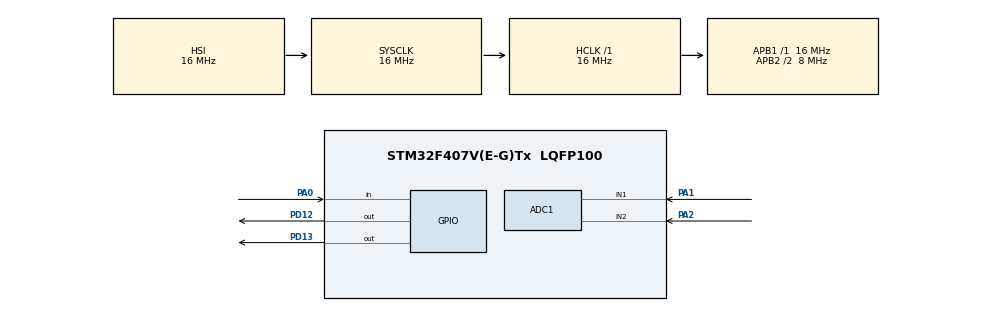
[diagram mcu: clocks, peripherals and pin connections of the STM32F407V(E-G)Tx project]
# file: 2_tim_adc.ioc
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ADC1.Channel-0\#ChannelRegularConversion=ADC_CHANNEL_1
ADC1.Channel-1\#ChannelRegularConversion=ADC_CHANNEL_2
ADC1.ContinuousConvMode=ENABLE
ADC1.NbrOfConversion=2
ADC1.NbrOfConversionFlag=1
ADC1.Rank-0\#ChannelRegularConversion=1
ADC1.Rank-1\#ChannelRegularConversion=2
ADC1.SamplingTime-0\#ChannelRegularConversion=ADC_SAMPLETIME_56CYCLES
ADC1.SamplingTime-1\#ChannelRegularConversion=ADC_SAMPLETIME_56CYCLES
ADC1.master=1
Mcu.Family=STM32F4
Mcu.Name=STM32F407V(E-G)Tx
Mcu.Package=LQFP100
NVIC.PriorityGroup=NVIC_PRIORITYGROUP_4
PA0-WKUP.Signal=GPIO_Input
PA1.Signal=ADCx_IN1
PA13.Mode=Serial_Wire
PA13.Signal=SYS_JTMS-SWDIO
PA14.Mode=Serial_Wire
PA14.Signal=SYS_JTCK-SWCLK
PA2.Signal=ADCx_IN2
PD12.Signal=GPIO_Output
PD13.Signal=GPIO_Output
ProjectManager.HeapSize=0x200
ProjectManager.StackSize=0x400
ProjectManager.TargetToolchain=MDK-ARM V5
RCC.48MHZClocksFreq_Value=25000000
RCC.AHBFreq_Value=16000000
RCC.APB1Freq_Value=16000000
RCC.APB1TimFreq_Value=16000000
RCC.APB2CLKDivider=RCC_HCLK_DIV2
RCC.APB2Freq_Value=8000000
RCC.APB2TimFreq_Value=16000000
RCC.CortexFreq_Value=16000000
RCC.HCLKFreq_Value=16000000
RCC.HSE_VALUE=8000000
RCC.HSI_VALUE=16000000
RCC.LSE_VALUE=32768
RCC.PLLI2SN=50
RCC.PLLM=8
RCC.PLLN=50
RCC.SYSCLKFreq_VALUE=16000000
RCC.VCOOutputFreq_Value=100000000
SH.ADCx_IN1.0=ADC1_IN1,IN1
SH.ADCx_IN2.0=ADC1_IN2,IN2
TIM2.Period=9999
TIM2.Prescaler=16000-1
VP_TIM2_VS_ClockSourceINT.Mode=Internal
board=custom

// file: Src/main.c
/* USER CODE BEGIN Header */
/**
  ******************************************************************************
  * @file           : main.c
  * @brief          : Main program body
  ******************************************************************************
  ** This notice applies to any and all portions of this file
  * that are not between comment pairs USER CODE BEGIN and
  * USER CODE END. Other portions of this file, whether
  * inserted by the user or by software development tools
  * are owned by their respective copyright owners.
  *
  * COPYRIGHT(c) 2020 STMicroelectronics
  *
  * Redistribution and use in source and binary forms, with or without modification,
  * are permitted provided that the following conditions are met:
  *   1. Redistributions of source code must retain the above copyright notice,
  *      this list of conditions and the following disclaimer.
  *   2. Redistributions in binary form must reproduce the above copyright notice,
  *      this list of conditions and the following disclaimer in the documentation
  *      and/or other materials provided with the distribution.
  *   3. Neither the name of STMicroelectronics nor the names of its contributors
  *      may be used to endorse or promote products derived from this software
  *      without specific prior written permission.
  *
  * THIS SOFTWARE IS PROVIDED BY THE COPYRIGHT HOLDERS AND CONTRIBUTORS "AS IS"
  * AND ANY EXPRESS OR IMPLIED WARRANTIES, INCLUDING, BUT NOT LIMITED TO, THE
  * IMPLIED WARRANTIES OF MERCHANTABILITY AND FITNESS FOR A PARTICULAR PURPOSE ARE
  * DISCLAIMED. IN NO EVENT SHALL THE COPYRIGHT HOLDER OR CONTRIBUTORS BE LIABLE
  * FOR ANY DIRECT, INDIRECT, INCIDENTAL, SPECIAL, EXEMPLARY, OR CONSEQUENTIAL
  * DAMAGES (INCLUDING, BUT NOT LIMITED TO, PROCUREMENT OF SUBSTITUTE GOODS OR
  * SERVICES; LOSS OF USE, DATA, OR PROFITS; OR BUSINESS INTERRUPTION) HOWEVER
  * CAUSED AND ON ANY THEORY OF LIABILITY, WHETHER IN CONTRACT, STRICT LIABILITY,
  * OR TORT (INCLUDING NEGLIGENCE OR OTHERWISE) ARISING IN ANY WAY OUT OF THE USE
  * OF THIS SOFTWARE, EVEN IF ADVISED OF THE POSSIBILITY OF SUCH DAMAGE.
  *
  ******************************************************************************
  */
/* USER CODE END Header */

#include "main.h"

/* USER CODE BEGIN PD */
uint16_t sayac=0,count=0;
uint16_t channel_1,channel_2 ; // kanal 1 2  datasi
/* USER CODE END PD */

ADC_HandleTypeDef hadc1;

TIM_HandleTypeDef htim2;

void SystemClock_Config(void);
static void MX_GPIO_Init(void);
static void MX_TIM2_Init(void);
static void MX_ADC1_Init(void);
/* USER CODE BEGIN PFP */

void Buton_Oku(void)
{
	  while((HAL_GPIO_ReadPin(GPIOA,GPIO_PIN_0))!=0 )
  {
    	HAL_TIM_Base_Start(&htim2);
	    sayac= __HAL_TIM_GetCounter(&htim2);

	 while(sayac>=3000 )
	 {

			 HAL_GPIO_WritePin(GPIOD,GPIO_PIN_12|GPIO_PIN_13,GPIO_PIN_SET);
			 channel_1 = HAL_ADC_GetValue(&hadc1);
		     channel_2 = HAL_ADC_GetValue(&hadc1);
		     HAL_Delay(500);

		     if( count==2 )
				{
					__HAL_TIM_SetCounter(&htim2,0);
					sayac= __HAL_TIM_GetCounter(&htim2);
					HAL_GPIO_WritePin(GPIOD,GPIO_PIN_12|GPIO_PIN_13,GPIO_PIN_RESET);
					count=0;
	 			}

	  }

  }
}

int main(void)
{

  /* MCU Configuration--------------------------------------------------------*/

  /* Reset of all peripherals, Initializes the Flash interface and the Systick. */
  HAL_Init();

  /* Configure the system clock */
  SystemClock_Config();

  /* Initialize all configured peripherals */
  MX_GPIO_Init();
  MX_TIM2_Init();
  MX_ADC1_Init();
  /* USER CODE BEGIN 2 */
  HAL_ADC_Start(&hadc1); // adc yi start ettik. ADC1'i.
  /* USER CODE END 2 */

  /* Infinite loop */
  while (1)
  {
  Buton_Oku();
  }
}

void SystemClock_Config(void)
{
  RCC_OscInitTypeDef RCC_OscInitStruct = {0};
  RCC_ClkInitTypeDef RCC_ClkInitStruct = {0};

  /**Configure the main internal regulator output voltage
  */
  __HAL_RCC_PWR_CLK_ENABLE();
  __HAL_PWR_VOLTAGESCALING_CONFIG(PWR_REGULATOR_VOLTAGE_SCALE1);
  /**Initializes the CPU, AHB and APB busses clocks
  */
  RCC_OscInitStruct.OscillatorType = RCC_OSCILLATORTYPE_HSI;
  RCC_OscInitStruct.HSIState = RCC_HSI_ON;
  RCC_OscInitStruct.HSICalibrationValue = RCC_HSICALIBRATION_DEFAULT;
  RCC_OscInitStruct.PLL.PLLState = RCC_PLL_NONE;
  if (HAL_RCC_OscConfig(&RCC_OscInitStruct) != HAL_OK)
  {
    Error_Handler();
  }
  /**Initializes the CPU, AHB and APB busses clocks
  */
  RCC_ClkInitStruct.ClockType = RCC_CLOCKTYPE_HCLK|RCC_CLOCKTYPE_SYSCLK
                              |RCC_CLOCKTYPE_PCLK1|RCC_CLOCKTYPE_PCLK2;
  RCC_ClkInitStruct.SYSCLKSource = RCC_SYSCLKSOURCE_HSI;
  RCC_ClkInitStruct.AHBCLKDivider = RCC_SYSCLK_DIV1;
  RCC_ClkInitStruct.APB1CLKDivider = RCC_HCLK_DIV1;
  RCC_ClkInitStruct.APB2CLKDivider = RCC_HCLK_DIV2;

  if (HAL_RCC_ClockConfig(&RCC_ClkInitStruct, FLASH_LATENCY_0) != HAL_OK)
  {
    Error_Handler();
  }
}

static void MX_ADC1_Init(void)
{

  ADC_ChannelConfTypeDef sConfig = {0};

  /**Configure the global features of the ADC (Clock, Resolution, Data Alignment and number of conversion)
  */
  hadc1.Instance = ADC1;
  hadc1.Init.ClockPrescaler = ADC_CLOCK_SYNC_PCLK_DIV2;
  hadc1.Init.Resolution = ADC_RESOLUTION_12B;
  hadc1.Init.ScanConvMode = ENABLE;
  hadc1.Init.ContinuousConvMode = ENABLE;
  hadc1.Init.DiscontinuousConvMode = DISABLE;
  hadc1.Init.ExternalTrigConvEdge = ADC_EXTERNALTRIGCONVEDGE_NONE;
  hadc1.Init.ExternalTrigConv = ADC_SOFTWARE_START;
  hadc1.Init.DataAlign = ADC_DATAALIGN_RIGHT;
  hadc1.Init.NbrOfConversion = 2;
  hadc1.Init.DMAContinuousRequests = DISABLE;
  hadc1.Init.EOCSelection = ADC_EOC_SINGLE_CONV;
  if (HAL_ADC_Init(&hadc1) != HAL_OK)
  {
    Error_Handler();
  }
  /**Configure for the selected ADC regular channel its corresponding rank in the sequencer and its sample time.
  */
  sConfig.Channel = ADC_CHANNEL_1;
  sConfig.Rank = 1;
  sConfig.SamplingTime = ADC_SAMPLETIME_3CYCLES;
  if (HAL_ADC_ConfigChannel(&hadc1, &sConfig) != HAL_OK)
  {
    Error_Handler();
  }
  /**Configure for the selected ADC regular channel its corresponding rank in the sequencer and its sample time.
  */
  sConfig.Channel = ADC_CHANNEL_2;
  sConfig.Rank = 2;
  if (HAL_ADC_ConfigChannel(&hadc1, &sConfig) != HAL_OK)
  {
    Error_Handler();
  }

}

static void MX_TIM2_Init(void)
{

  TIM_ClockConfigTypeDef sClockSourceConfig = {0};
  TIM_MasterConfigTypeDef sMasterConfig = {0};

  htim2.Instance = TIM2;
  htim2.Init.Prescaler = 16000-1;
  htim2.Init.CounterMode = TIM_COUNTERMODE_UP;
  htim2.Init.Period = 9999;
  htim2.Init.ClockDivision = TIM_CLOCKDIVISION_DIV1;
  if (HAL_TIM_Base_Init(&htim2) != HAL_OK)
  {
    Error_Handler();
  }
  sClockSourceConfig.ClockSource = TIM_CLOCKSOURCE_INTERNAL;
  if (HAL_TIM_ConfigClockSource(&htim2, &sClockSourceConfig) != HAL_OK)
  {
    Error_Handler();
  }
  sMasterConfig.MasterOutputTrigger = TIM_TRGO_RESET;
  sMasterConfig.MasterSlaveMode = TIM_MASTERSLAVEMODE_DISABLE;
  if (HAL_TIMEx_MasterConfigSynchronization(&htim2, &sMasterConfig) != HAL_OK)
  {
    Error_Handler();
  }

}

static void MX_GPIO_Init(void)
{
  GPIO_InitTypeDef GPIO_InitStruct = {0};

  /* GPIO Ports Clock Enable */
  __HAL_RCC_GPIOA_CLK_ENABLE();
  __HAL_RCC_GPIOD_CLK_ENABLE();

  /*Configure GPIO pin Output Level */
  HAL_GPIO_WritePin(GPIOD, GPIO_PIN_12|GPIO_PIN_13, GPIO_PIN_RESET);

  /*Configure GPIO pin : PA0 */
  GPIO_InitStruct.Pin = GPIO_PIN_0;
  GPIO_InitStruct.Mode = GPIO_MODE_INPUT;
  GPIO_InitStruct.Pull = GPIO_NOPULL;
  HAL_GPIO_Init(GPIOA, &GPIO_InitStruct);

  /*Configure GPIO pins : PD12 PD13 */
  GPIO_InitStruct.Pin = GPIO_PIN_12|GPIO_PIN_13;
  GPIO_InitStruct.Mode = GPIO_MODE_OUTPUT_PP;
  GPIO_InitStruct.Pull = GPIO_NOPULL;
  GPIO_InitStruct.Speed = GPIO_SPEED_FREQ_LOW;
  HAL_GPIO_Init(GPIOD, &GPIO_InitStruct);

}

void Error_Handler(void)
{
}

/************************ (C) COPYRIGHT STMicroelectronics *****END OF FILE****/
